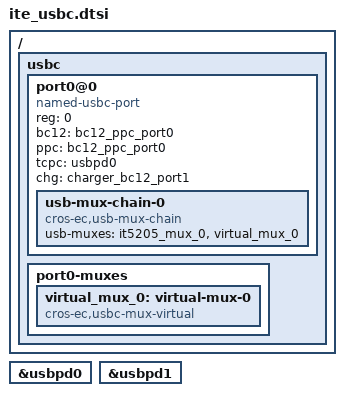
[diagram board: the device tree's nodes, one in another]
/* Copyright 2021 The ChromiumOS Authors
 * Use of this source code is governed by a BSD-style license that can be
 * found in the LICENSE file.
 */

/ {
	usbc {
		#address-cells = <1>;
		#size-cells = <0>;

		port0@0 {
			compatible = "named-usbc-port";
			reg = <0>;
			bc12 = <&bc12_ppc_port0>;
			ppc = <&bc12_ppc_port0>;
			tcpc = <&usbpd0>;
			chg = <&charger_bc12_port1>;
			usb-mux-chain-0 {
				compatible = "cros-ec,usb-mux-chain";
				usb-muxes = <&it5205_mux_0 &virtual_mux_0>;
			};
		};
		port0-muxes {
			virtual_mux_0: virtual-mux-0 {
				compatible = "cros-ec,usbc-mux-virtual";
			};
		};
	};
};

&usbpd0 {
	status = "okay";
};

&usbpd1 {
	status = "okay";
};
